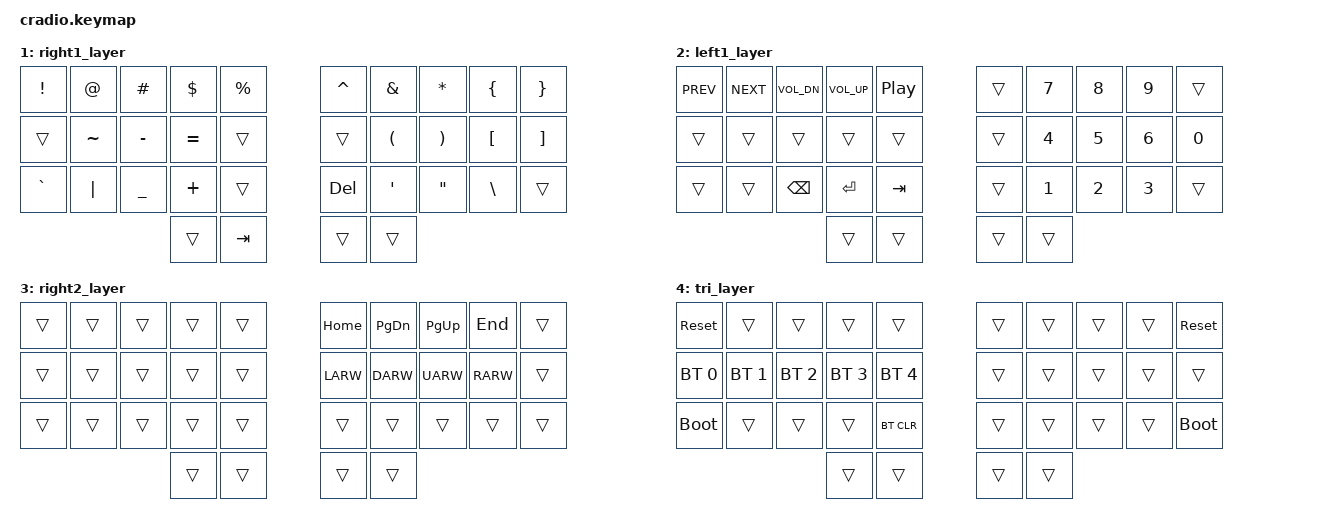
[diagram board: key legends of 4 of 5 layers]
// Copyright (c) 2022 The ZMK Contributors
// SPDX-License-Identifier: MIT

#include <behaviors.dtsi>
#include <dt-bindings/zmk/keys.h>
#include <dt-bindings/zmk/bt.h>

// Home row mods macro
#define HRML(k1,k2,k3,k4) &ht LSHFT k1  &ht LCTRL k2  &ht LALT k3  &ht LGUI k4
#define HRMR(k1,k2,k3,k4) &ht RGUI k1  &ht RALT k2  &ht RCTRL k3  &ht RSHFT k4
#define DEFAULT 0
#define RIGHT1   1
#define LEFT1    2
#define RIGHT2   3
#define TRI      4

&lt {
    tapping-term-ms = <120>;
};

/ {
    combos {
        #include "combos.dtsi"
    };

    behaviors {
        ht: hold_tap {
            label = "hold_tap";
            compatible = "zmk,behavior-hold-tap";
            #binding-cells = <2>;
            flavor = "tap-preferred";
            // flavor = "balanced";
            // flavor = "hold-preferred";
            //tapping-term-ms = <220>;
            tapping-term-ms = <190>;
            quick-tap-ms = <150>;
            require-prior-idle-ms = <100>;
            bindings = <&kp>, <&kp>;
        };
    };

    conditional_layers {
        compatible = "zmk,conditional-layers";
        tri_layer {
            if-layers = <RIGHT1 LEFT1>;
            then-layer = <TRI>;
        };
    };

    keymap {
        compatible = "zmk,keymap";
        default_layer {
            bindings = <
        //╭──────────┬──────────┬──────────┬──────────┬──────────╮        ╭──────────┬──────────┬──────────┬──────────┬──────────╮
        //│  Q       │  W       │  E       │  R       │  T       │        │  Y       │  U       │  I       │  O       │  P       │
            &kp Q      &kp W      &kp E      &kp R      &kp T               &kp Y      &kp U      &kp I      &kp O      &kp P
        //├──────────┼──────────┼──────────┼──────────┼──────────┤        ├──────────┼──────────┼──────────┼──────────┼──────────┤
        //│  A       │  S       │  D       │  F       │  G       │        │  H       │  J       │  K       │  L       │ ; :      │
            HRML(A,        S,         D,         F)     &kp G               &kp H      HRMR(J,        K,         L,        SEMI)
        //├──────────┼──────────┼──────────┼──────────┼──────────┤        ├──────────┼──────────┼──────────┼──────────┼──────────┤
        //│  Z       │  X       │  C       │  V       │  B       │        │  N       │  M       │ , <      │ . >      │ / ?      │
            &kp Z      &kp X      &kp C      &kp V      &kp B               &kp N      &kp M      &kp COMMA  &kp DOT    &kp FSLH
        //╰──────────┴──────────┴──────────┼──────────┼──────────┤        ├──────────┼──────────┼──────────┴──────────┴──────────╯
                                 &lt LEFT1 ESC    &mt LS(LC(LALT)) SPACE  &lt RIGHT2 BSPC   &lt RIGHT1 ENTER
        //                                 ╰──────────┴──────────╯        ╰──────────┴──────────╯
            >;
        };

        right1_layer {
            bindings = <
        //╭──────────┬──────────┬──────────┬──────────┬──────────╮   ╭──────────┬──────────┬──────────┬──────────┬──────────╮
        //│ !        │  @       │  #       │  $       │ %        │   │  ^       │  &       │  *       │  {       │  }       │
            &kp EXCL   &kp AT     &kp HASH   &kp DLLR   &kp PRCNT      &kp CARET  &kp AMPS   &kp ASTRK  &kp LBRC   &kp RBRC
        //├──────────┼──────────┼──────────┼──────────┼──────────┤   ├──────────┼──────────┼──────────┼──────────┼──────────┤
        //│          │  ~       │  -       │  =       │          │   │          │  (       │  )       │  [       │  ]       │
            &trans     &kp TILDE  &kp MINUS  &kp EQUAL  &trans         &trans     &kp LPAR   &kp RPAR   &kp LBKT   &kp RBKT
        //├──────────┼──────────┼──────────┼──────────┼──────────┤   ├──────────┼──────────┼──────────┼──────────┼──────────┤
        //│ `        │ |        │ _        │ +        │          │   │          │  '       │  "       │  \       │          │
            &kp GRAVE  &kp PIPE   &kp UNDER  &kp PLUS   &trans         &kp  DEL   &kp SQT    &kp DQT    &kp BSLH   &trans
        //╰──────────┴──────────┴──────────┼──────────┼──────────┤   ├──────────┼──────────┼──────────┴──────────┴──────────╯
                                             &trans     &kp TAB         &trans     &trans
        //                                 ╰──────────┴──────────╯   ╰──────────┴──────────╯
            >;
        };


        left1_layer {
            bindings = <
        //╭──────────┬──────────┬──────────┬──────────┬──────────╮   ╭──────────┬──────────┬──────────┬──────────┬──────────╮
        //│ Prev song│ Next song│ Vol Down │ Vol UP   │ Pause    │   │          │  7       │  8       │  9       │          │
          &kp C_PREV &kp C_NEXT &kp C_VOL_DN &kp C_VOL_UP &kp C_PP      &trans     &kp N7     &kp N8     &kp N9     &trans    
        // &bt BT_SEL 0  &bt BT_SEL 1 &bt BT_SEL 2 &bt BT_SEL 3 &bt BT_SEL 4    &trans     &kp N7     &kp N8     &kp N9     &trans 
        //├──────────┼──────────┼──────────┼──────────┼──────────┤   ├──────────┼──────────┼──────────┼──────────┼──────────┤
        //│          │          │          │          │          │   │          │  4       │  5       │  6       │  0       │
            &trans     &trans     &trans     &trans     &trans         &trans     &kp N4     &kp N5     &kp N6     &kp N0
        //├──────────┼──────────┼──────────┼──────────┼──────────┤   ├──────────┼──────────┼──────────┼──────────┼──────────┤
        //│          │          │Backspace │ ENTER    │ TAB      │   │          │  1       │  2       │  3       │          │
            &trans     &trans     &kp BSPC   &kp ENTER  &kp TAB        &trans     &kp N1     &kp N2     &kp N3     &trans
        //╰──────────┴──────────┴──────────┼──────────┼──────────┤   ├──────────┼──────────┼──────────┴──────────┴──────────╯
                                             &trans     &trans         &trans     &trans
        //                                 ╰──────────┴──────────╯   ╰──────────┴──────────╯
            >;
        };

        right2_layer {
            bindings = <
        //╭──────────┬──────────┬──────────┬──────────┬──────────╮   ╭──────────┬──────────┬──────────┬──────────┬──────────╮
        //│          │          │          │          │          │   │ HOME     │ PAGE DN  │ PAGE UP  │ END      │          │
            &trans     &trans     &trans     &trans    &trans          &kp HOME   &kp PG_DN  &kp PG_UP  &kp END   &trans
        //├──────────┼──────────┼──────────┼──────────┼──────────┤   ├──────────┼──────────┼──────────┼──────────┼──────────┤
        //│          │          │          │          │          │   │ LEFT     │ DOWN     │ UP       │ RIGHT    │          │
            &trans     &trans     &trans     &trans    &trans          &kp LARW   &kp DARW   &kp UARW   &kp RARW  &trans
        //├──────────┼──────────┼──────────┼──────────┼──────────┤   ├──────────┼──────────┼──────────┼──────────┼──────────┤
        //│          │          │          │          │          │   │          │          │          │          │          │
            &trans     &trans     &trans     &trans    &trans          &trans     &trans     &trans     &trans    &trans
        //╰──────────┴──────────┴──────────┼──────────┼──────────┤   ├──────────┼──────────┼──────────┴──────────┴──────────╯
                                             &trans     &trans         &trans     &trans
        //                                 ╰──────────┴──────────╯   ╰──────────┴──────────╯
            >;
        };

        tri_layer {
            bindings = <
        //╭──────────┬──────────┬──────────┬──────────┬──────────╮   ╭──────────┬──────────┬──────────┬──────────┬──────────╮
        //│ RESET    │          │          │          │          │   │          │          │          │          │  RESET   │
           &sys_reset  &trans     &trans     &trans    &trans          &trans     &trans     &trans     &trans    &sys_reset
        //├──────────┼──────────┼──────────┼──────────┼──────────┤   ├──────────┼──────────┼──────────┼──────────┼──────────┤
        //│PROFILE 0 │PROFILE 1 │PROFILE 2 │PROFILE 3 │PROFILE 4 │   │          │          │          │          │          │
    &bt BT_SEL 0  &bt BT_SEL 1 &bt BT_SEL 2 &bt BT_SEL 3 &bt BT_SEL 4 &trans     &trans     &trans     &trans    &trans
        //├──────────┼──────────┼──────────┼──────────┼──────────┤   ├──────────┼──────────┼──────────┼──────────┼──────────┤
        //│BOOTLOADER│          │          │          │ CLEAR BT │   │          │          │          │          │BOOTLOADER│
          &bootloader  &trans     &trans    &trans     &bt BT_CLR      &trans     &trans     &trans     &trans    &bootloader
        //╰──────────┴──────────┴──────────┼──────────┼──────────┤   ├──────────┼──────────┼──────────┴──────────┴──────────╯
                                             &trans     &trans         &trans     &trans
        //                                 ╰──────────┴──────────╯   ╰──────────┴──────────╯
            >;
        };

    };
};
